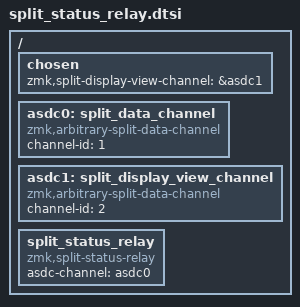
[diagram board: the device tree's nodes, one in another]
// The halves are split peripherals, so they only know the active layer and
// the other half's battery if the dongle relays them over this channel
/ {
    chosen {
        zmk,split-display-view-channel = &asdc1;
    };

    asdc0: split_data_channel {
        compatible = "zmk,arbitrary-split-data-channel";
        channel-id = <1>;
        status = "okay";
    };

    // Carries modifiers and lock indicators, which the status relay does not send
    asdc1: split_display_view_channel {
        compatible = "zmk,arbitrary-split-data-channel";
        channel-id = <2>;
        status = "okay";
    };

    split_status_relay {
        compatible = "zmk,split-status-relay";
        asdc-channel = <&asdc0>;
        status = "okay";
    };
};
